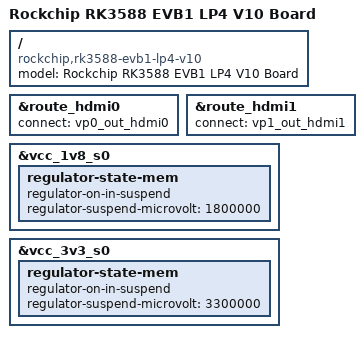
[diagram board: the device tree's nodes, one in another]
// SPDX-License-Identifier: (GPL-2.0+ OR MIT)
/*
 * Copyright (c) 2021 Rockchip Electronics Co., Ltd.
 *
 */

/dts-v1/;

#include "rk3588-evb1-lp4.dtsi"
#include "rk3588-evb1-imx415.dtsi"
#include "rk3588-linux.dtsi"

/ {
	model = "Rockchip RK3588 EVB1 LP4 V10 Board";
	compatible = "rockchip,rk3588-evb1-lp4-v10", "rockchip,rk3588";
};

&route_hdmi0 {
	status = "okay";
	connect = <&vp0_out_hdmi0>;
	/delete-property/ force-output;
	/delete-node/ force_timing;
};

&route_hdmi1 {
	status = "okay";
	connect = <&vp1_out_hdmi1>;
	/delete-property/ force-output;
	/delete-node/ force_timing;
};

&vcc_1v8_s0 {
	/delete-property/ regulator-state-mem;
	regulator-state-mem {
		regulator-on-in-suspend;
		regulator-suspend-microvolt = <1800000>;
	};
};

&vcc_3v3_s0 {
	/delete-property/ regulator-state-mem;
	regulator-state-mem {
		regulator-on-in-suspend;
		regulator-suspend-microvolt = <3300000>;
	};
};
